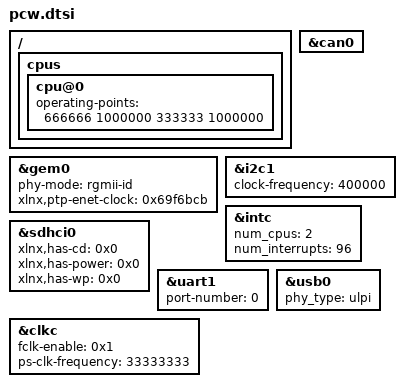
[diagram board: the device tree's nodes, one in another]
/*
 * CAUTION: This file is automatically generated by Xilinx.
 * Version:  
 * Today is: Thu Nov 16 21:47:27 2017
*/


/ {
	cpus {
		cpu@0 {
			operating-points = <666666 1000000 333333 1000000>;
		};
	};
};
&can0 {
	status = "okay";
};
&gem0 {
	phy-mode = "rgmii-id";
	status = "okay";
	xlnx,ptp-enet-clock = <0x69f6bcb>;
};
&i2c1 {
	clock-frequency = <400000>;
	status = "okay";
};
&intc {
	num_cpus = <2>;
	num_interrupts = <96>;
};
&sdhci0 {
	status = "okay";
	xlnx,has-cd = <0x0>;
	xlnx,has-power = <0x0>;
	xlnx,has-wp = <0x0>;
};
&uart1 {
	device_type = "serial";
	port-number = <0>;
	status = "okay";
};
&usb0 {
	phy_type = "ulpi";
	status = "okay";
};
&clkc {
	fclk-enable = <0x1>;
	ps-clk-frequency = <33333333>;
};
